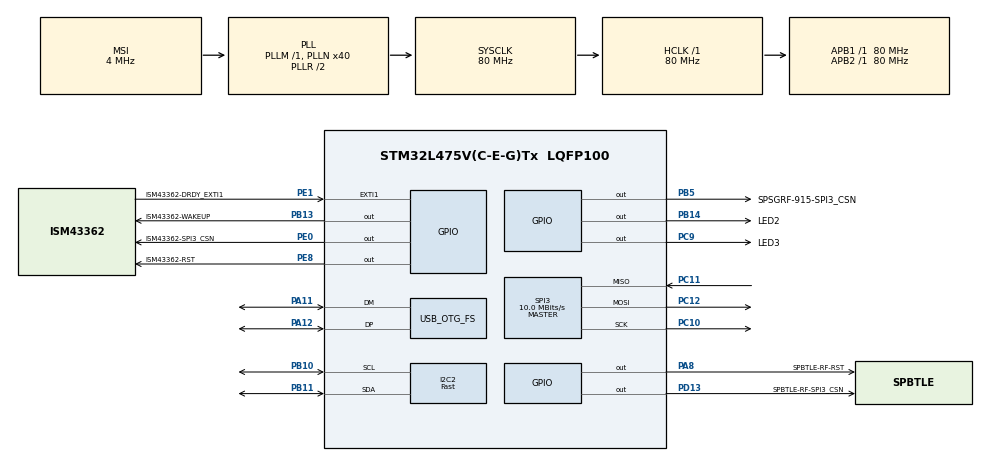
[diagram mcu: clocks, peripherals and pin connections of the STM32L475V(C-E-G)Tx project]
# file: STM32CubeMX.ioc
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Dma.I2C2_RX.0.Direction=DMA_PERIPH_TO_MEMORY
Dma.I2C2_RX.0.Instance=DMA1_Channel5
Dma.I2C2_RX.0.MemDataAlignment=DMA_MDATAALIGN_BYTE
Dma.I2C2_RX.0.MemInc=DMA_MINC_ENABLE
Dma.I2C2_RX.0.Mode=DMA_NORMAL
Dma.I2C2_RX.0.PeriphDataAlignment=DMA_PDATAALIGN_BYTE
Dma.I2C2_RX.0.PeriphInc=DMA_PINC_DISABLE
Dma.I2C2_RX.0.Priority=DMA_PRIORITY_LOW
Dma.I2C2_TX.1.Direction=DMA_MEMORY_TO_PERIPH
Dma.I2C2_TX.1.Instance=DMA1_Channel4
Dma.I2C2_TX.1.MemDataAlignment=DMA_MDATAALIGN_BYTE
Dma.I2C2_TX.1.MemInc=DMA_MINC_ENABLE
Dma.I2C2_TX.1.Mode=DMA_NORMAL
Dma.I2C2_TX.1.PeriphDataAlignment=DMA_PDATAALIGN_BYTE
Dma.I2C2_TX.1.PeriphInc=DMA_PINC_DISABLE
Dma.I2C2_TX.1.Priority=DMA_PRIORITY_LOW
Dma.Request0=I2C2_RX
Dma.Request1=I2C2_TX
I2C2.I2C_Speed_Mode=I2C_Fast
I2C2.Timing=0x00702991
Mcu.Family=STM32L4
Mcu.Name=STM32L475V(C-E-G)Tx
Mcu.Package=LQFP100
NVIC.DMA1_Channel4_IRQn=true\:14\:0\:true\:false\:true\:false\:true
NVIC.DMA1_Channel5_IRQn=true\:14\:0\:true\:false\:true\:false\:true
NVIC.EXTI1_IRQn=true\:13\:0\:true\:false\:true\:true\:true
NVIC.I2C2_ER_IRQn=true\:14\:0\:true\:false\:true\:true\:true
NVIC.I2C2_EV_IRQn=true\:14\:0\:true\:false\:true\:true\:true
NVIC.OTG_FS_IRQn=true\:14\:0\:true\:false\:true\:false\:true
NVIC.PriorityGroup=NVIC_PRIORITYGROUP_4
NVIC.SPI3_IRQn=true\:13\:0\:true\:false\:true\:true\:true
NVIC.TIM2_IRQn=true\:0\:0\:false\:false\:true\:false\:true
NVIC.TimeBase=TIM2_IRQn
NVIC.TimeBaseIP=TIM2
PA11.Mode=Device_Only
PA11.Signal=USB_OTG_FS_DM
PA12.Mode=Device_Only
PA12.Signal=USB_OTG_FS_DP
PA8.GPIO_Label=SPBTLE-RF-RST
PA8.PinState=GPIO_PIN_SET
PA8.Signal=GPIO_Output
PB10.GPIO_PuPdOD=GPIO_NOPULL
PB10.GPIO_Speed=GPIO_SPEED_FREQ_LOW
PB10.Mode=I2C
PB10.Signal=I2C2_SCL
PB11.GPIO_PuPdOD=GPIO_NOPULL
PB11.GPIO_Speed=GPIO_SPEED_FREQ_LOW
PB11.Mode=I2C
PB11.Signal=I2C2_SDA
PB13.GPIO_Label=ISM43362-WAKEUP
PB13.PinState=GPIO_PIN_SET
PB13.Signal=GPIO_Output
PB14.GPIO_Label=LED2
PB14.Signal=GPIO_Output
PB5.GPIO_Label=SPSGRF-915-SPI3_CSN
PB5.PinState=GPIO_PIN_SET
PB5.Signal=GPIO_Output
PC10.GPIO_Speed=GPIO_SPEED_FREQ_MEDIUM
PC10.Mode=Full_Duplex_Master
PC10.Signal=SPI3_SCK
PC11.GPIO_PuPd=GPIO_PULLUP
PC11.GPIO_Speed=GPIO_SPEED_FREQ_MEDIUM
PC11.Mode=Full_Duplex_Master
PC11.Signal=SPI3_MISO
PC12.GPIO_Speed=GPIO_SPEED_FREQ_MEDIUM
PC12.Mode=Full_Duplex_Master
PC12.Signal=SPI3_MOSI
PC9.GPIO_Label=LED3
PC9.GPIO_ModeDefaultOutputPP=GPIO_MODE_OUTPUT_PP
PC9.GPIO_PuPd=GPIO_NOPULL
PC9.Signal=GPIO_Output
PD13.GPIO_Label=SPBTLE-RF-SPI3_CSN
PD13.PinState=GPIO_PIN_SET
PD13.Signal=GPIO_Output
PE0.GPIO_Label=ISM43362-SPI3_CSN
PE0.GPIO_Speed=GPIO_SPEED_FREQ_MEDIUM
PE0.PinState=GPIO_PIN_SET
PE0.Signal=GPIO_Output
PE1.GPIO_Label=ISM43362-DRDY_EXTI1
PE1.Signal=GPXTI1
PE8.GPIO_Label=ISM43362-RST
PE8.PinState=GPIO_PIN_SET
PE8.Signal=GPIO_Output
ProjectManager.HeapSize=0x0
ProjectManager.StackSize=0x400
ProjectManager.TargetToolchain=STM32CubeIDE
RCC.ADCFreq_Value=48000000
RCC.AHBFreq_Value=80000000
RCC.APB1Freq_Value=80000000
RCC.APB1TimFreq_Value=80000000
RCC.APB2Freq_Value=80000000
RCC.APB2TimFreq_Value=80000000
RCC.CortexFreq_Value=80000000
RCC.HCLKFreq_Value=80000000
RCC.HSE_VALUE=8000000
RCC.HSI_VALUE=16000000
RCC.LSE_VALUE=32768
RCC.MSI_VALUE=4000000
RCC.PLLN=40
RCC.PLLSAI1N=24
RCC.SYSCLKFreq_VALUE=80000000
RCC.SYSCLKSource=RCC_SYSCLKSOURCE_PLLCLK
RCC.USBFreq_Value=48000000
RCC.VCOOutputFreq_Value=160000000
SPI3.BaudRatePrescaler=SPI_BAUDRATEPRESCALER_8
SPI3.CalculateBaudRate=10.0 MBits/s
SPI3.DataSize=SPI_DATASIZE_16BIT
SPI3.Direction=SPI_DIRECTION_2LINES
SPI3.Mode=SPI_MODE_MASTER
SPI3.VirtualType=VM_MASTER
USB_DEVICE.APP_TX_DATA_SIZE=2048
USB_DEVICE.CLASS_NAME_FS=CDC
USB_DEVICE.VirtualMode=Cdc
USB_DEVICE.VirtualModeFS=Cdc_FS
USB_OTG_FS.VirtualMode=Device_Only
VP_RNG_VS_RNG.Mode=RNG_Activate
VP_SYS_VS_tim2.Mode=TIM2
VP_USB_DEVICE_VS_USB_DEVICE_CDC_FS.Mode=CDC_FS
board=custom

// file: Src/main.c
/* USER CODE BEGIN Header */
/**
  ******************************************************************************
  * @file           : main.c
  * @brief          : Main program body
  ******************************************************************************
  ** This notice applies to any and all portions of this file
  * that are not between comment pairs USER CODE BEGIN and
  * USER CODE END. Other portions of this file, whether
  * inserted by the user or by software development tools
  * are owned by their respective copyright owners.
  *
  * COPYRIGHT(c) 2019 STMicroelectronics
  *
  * Redistribution and use in source and binary forms, with or without modification,
  * are permitted provided that the following conditions are met:
  *   1. Redistributions of source code must retain the above copyright notice,
  *      this list of conditions and the following disclaimer.
  *   2. Redistributions in binary form must reproduce the above copyright notice,
  *      this list of conditions and the following disclaimer in the documentation
  *      and/or other materials provided with the distribution.
  *   3. Neither the name of STMicroelectronics nor the names of its contributors
  *      may be used to endorse or promote products derived from this software
  *      without specific prior written permission.
  *
  * THIS SOFTWARE IS PROVIDED BY THE COPYRIGHT HOLDERS AND CONTRIBUTORS "AS IS"
  * AND ANY EXPRESS OR IMPLIED WARRANTIES, INCLUDING, BUT NOT LIMITED TO, THE
  * IMPLIED WARRANTIES OF MERCHANTABILITY AND FITNESS FOR A PARTICULAR PURPOSE ARE
  * DISCLAIMED. IN NO EVENT SHALL THE COPYRIGHT HOLDER OR CONTRIBUTORS BE LIABLE
  * FOR ANY DIRECT, INDIRECT, INCIDENTAL, SPECIAL, EXEMPLARY, OR CONSEQUENTIAL
  * DAMAGES (INCLUDING, BUT NOT LIMITED TO, PROCUREMENT OF SUBSTITUTE GOODS OR
  * SERVICES; LOSS OF USE, DATA, OR PROFITS; OR BUSINESS INTERRUPTION) HOWEVER
  * CAUSED AND ON ANY THEORY OF LIABILITY, WHETHER IN CONTRACT, STRICT LIABILITY,
  * OR TORT (INCLUDING NEGLIGENCE OR OTHERWISE) ARISING IN ANY WAY OUT OF THE USE
  * OF THIS SOFTWARE, EVEN IF ADVISED OF THE POSSIBILITY OF SUCH DAMAGE.
  *
  ******************************************************************************
  */
/* USER CODE END Header */

#include "main.h"
#include "usb_device.h"

/* USER CODE BEGIN Includes */
#include "es_wifi_io.h"
#include "usbd_cdc_if.h"
#include "StartApplication.hpp"

/* USER CODE END Includes */

I2C_HandleTypeDef hi2c2;
DMA_HandleTypeDef hdma_i2c2_rx;
DMA_HandleTypeDef hdma_i2c2_tx;

RNG_HandleTypeDef hrng;

SPI_HandleTypeDef hspi3;

void SystemClock_Config(void);
static void MX_GPIO_Init(void);
static void MX_DMA_Init(void);
static void MX_SPI3_Init(void);
static void MX_RNG_Init(void);
static void MX_I2C2_Init(void);

int main(void)
{
  /* USER CODE BEGIN 1 */

	/* Note: When the RTOS scheduler is started, the main stack pointer (MSP) is reset,
	* effectively wiping out all stack/local main() variables and objects. Do not declare
	* any C/C++ objects here. If objects need to be declared here, then change the code
	* within prvPortStartFirstTask() to retain the MSP value.
	*/

  /* USER CODE END 1 */

  /* MCU Configuration--------------------------------------------------------*/

  /* Reset of all peripherals, Initializes the Flash interface and the Systick. */
  HAL_Init();

  /* Configure the system clock */
  SystemClock_Config();

  /* Initialize all configured peripherals */
  MX_GPIO_Init();
  MX_DMA_Init();
  MX_USB_DEVICE_Init();
  MX_SPI3_Init();
  MX_RNG_Init();
  MX_I2C2_Init();
  /* USER CODE BEGIN 2 */
  StartApplication();

  /* USER CODE END 2 */

  /* Infinite loop */
  while (1)
  {

  }
}

void SystemClock_Config(void)
{
  RCC_OscInitTypeDef RCC_OscInitStruct = {0};
  RCC_ClkInitTypeDef RCC_ClkInitStruct = {0};
  RCC_PeriphCLKInitTypeDef PeriphClkInit = {0};

  /** Initializes the CPU, AHB and APB busses clocks
  */
  RCC_OscInitStruct.OscillatorType = RCC_OSCILLATORTYPE_MSI;
  RCC_OscInitStruct.MSIState = RCC_MSI_ON;
  RCC_OscInitStruct.MSICalibrationValue = 0;
  RCC_OscInitStruct.MSIClockRange = RCC_MSIRANGE_6;
  RCC_OscInitStruct.PLL.PLLState = RCC_PLL_ON;
  RCC_OscInitStruct.PLL.PLLSource = RCC_PLLSOURCE_MSI;
  RCC_OscInitStruct.PLL.PLLM = 1;
  RCC_OscInitStruct.PLL.PLLN = 40;
  RCC_OscInitStruct.PLL.PLLP = RCC_PLLP_DIV7;
  RCC_OscInitStruct.PLL.PLLQ = RCC_PLLQ_DIV2;
  RCC_OscInitStruct.PLL.PLLR = RCC_PLLR_DIV2;
  if (HAL_RCC_OscConfig(&RCC_OscInitStruct) != HAL_OK)
  {
    Error_Handler();
  }
  /** Initializes the CPU, AHB and APB busses clocks
  */
  RCC_ClkInitStruct.ClockType = RCC_CLOCKTYPE_HCLK|RCC_CLOCKTYPE_SYSCLK
                              |RCC_CLOCKTYPE_PCLK1|RCC_CLOCKTYPE_PCLK2;
  RCC_ClkInitStruct.SYSCLKSource = RCC_SYSCLKSOURCE_PLLCLK;
  RCC_ClkInitStruct.AHBCLKDivider = RCC_SYSCLK_DIV1;
  RCC_ClkInitStruct.APB1CLKDivider = RCC_HCLK_DIV1;
  RCC_ClkInitStruct.APB2CLKDivider = RCC_HCLK_DIV1;

  if (HAL_RCC_ClockConfig(&RCC_ClkInitStruct, FLASH_LATENCY_4) != HAL_OK)
  {
    Error_Handler();
  }
  PeriphClkInit.PeriphClockSelection = RCC_PERIPHCLK_I2C2|RCC_PERIPHCLK_USB
                              |RCC_PERIPHCLK_RNG;
  PeriphClkInit.I2c2ClockSelection = RCC_I2C2CLKSOURCE_PCLK1;
  PeriphClkInit.UsbClockSelection = RCC_USBCLKSOURCE_PLLSAI1;
  PeriphClkInit.RngClockSelection = RCC_RNGCLKSOURCE_PLLSAI1;
  PeriphClkInit.PLLSAI1.PLLSAI1Source = RCC_PLLSOURCE_MSI;
  PeriphClkInit.PLLSAI1.PLLSAI1M = 1;
  PeriphClkInit.PLLSAI1.PLLSAI1N = 24;
  PeriphClkInit.PLLSAI1.PLLSAI1P = RCC_PLLP_DIV7;
  PeriphClkInit.PLLSAI1.PLLSAI1Q = RCC_PLLQ_DIV2;
  PeriphClkInit.PLLSAI1.PLLSAI1R = RCC_PLLR_DIV2;
  PeriphClkInit.PLLSAI1.PLLSAI1ClockOut = RCC_PLLSAI1_48M2CLK;
  if (HAL_RCCEx_PeriphCLKConfig(&PeriphClkInit) != HAL_OK)
  {
    Error_Handler();
  }
  /** Configure the main internal regulator output voltage
  */
  if (HAL_PWREx_ControlVoltageScaling(PWR_REGULATOR_VOLTAGE_SCALE1) != HAL_OK)
  {
    Error_Handler();
  }
}

static void MX_I2C2_Init(void)
{

  hi2c2.Instance = I2C2;
  hi2c2.Init.Timing = 0x00702991;
  hi2c2.Init.OwnAddress1 = 0;
  hi2c2.Init.AddressingMode = I2C_ADDRESSINGMODE_7BIT;
  hi2c2.Init.DualAddressMode = I2C_DUALADDRESS_DISABLE;
  hi2c2.Init.OwnAddress2 = 0;
  hi2c2.Init.OwnAddress2Masks = I2C_OA2_NOMASK;
  hi2c2.Init.GeneralCallMode = I2C_GENERALCALL_DISABLE;
  hi2c2.Init.NoStretchMode = I2C_NOSTRETCH_DISABLE;
  if (HAL_I2C_Init(&hi2c2) != HAL_OK)
  {
    Error_Handler();
  }
  /** Configure Analogue filter
  */
  if (HAL_I2CEx_ConfigAnalogFilter(&hi2c2, I2C_ANALOGFILTER_ENABLE) != HAL_OK)
  {
    Error_Handler();
  }
  /** Configure Digital filter
  */
  if (HAL_I2CEx_ConfigDigitalFilter(&hi2c2, 0) != HAL_OK)
  {
    Error_Handler();
  }

}

static void MX_RNG_Init(void)
{

  hrng.Instance = RNG;
  if (HAL_RNG_Init(&hrng) != HAL_OK)
  {
    Error_Handler();
  }

}

static void MX_SPI3_Init(void)
{

  /* SPI3 parameter configuration*/
  hspi3.Instance = SPI3;
  hspi3.Init.Mode = SPI_MODE_MASTER;
  hspi3.Init.Direction = SPI_DIRECTION_2LINES;
  hspi3.Init.DataSize = SPI_DATASIZE_16BIT;
  hspi3.Init.CLKPolarity = SPI_POLARITY_LOW;
  hspi3.Init.CLKPhase = SPI_PHASE_1EDGE;
  hspi3.Init.NSS = SPI_NSS_SOFT;
  hspi3.Init.BaudRatePrescaler = SPI_BAUDRATEPRESCALER_8;
  hspi3.Init.FirstBit = SPI_FIRSTBIT_MSB;
  hspi3.Init.TIMode = SPI_TIMODE_DISABLE;
  hspi3.Init.CRCCalculation = SPI_CRCCALCULATION_DISABLE;
  hspi3.Init.CRCPolynomial = 7;
  hspi3.Init.CRCLength = SPI_CRC_LENGTH_DATASIZE;
  hspi3.Init.NSSPMode = SPI_NSS_PULSE_ENABLE;
  if (HAL_SPI_Init(&hspi3) != HAL_OK)
  {
    Error_Handler();
  }

}

static void MX_DMA_Init(void)
{

  /* DMA controller clock enable */
  __HAL_RCC_DMA1_CLK_ENABLE();

  /* DMA interrupt init */
  /* DMA1_Channel4_IRQn interrupt configuration */
  HAL_NVIC_SetPriority(DMA1_Channel4_IRQn, 14, 0);
  HAL_NVIC_EnableIRQ(DMA1_Channel4_IRQn);
  /* DMA1_Channel5_IRQn interrupt configuration */
  HAL_NVIC_SetPriority(DMA1_Channel5_IRQn, 14, 0);
  HAL_NVIC_EnableIRQ(DMA1_Channel5_IRQn);

}

static void MX_GPIO_Init(void)
{
  GPIO_InitTypeDef GPIO_InitStruct = {0};

  /* GPIO Ports Clock Enable */
  __HAL_RCC_GPIOE_CLK_ENABLE();
  __HAL_RCC_GPIOB_CLK_ENABLE();
  __HAL_RCC_GPIOD_CLK_ENABLE();
  __HAL_RCC_GPIOC_CLK_ENABLE();
  __HAL_RCC_GPIOA_CLK_ENABLE();

  /*Configure GPIO pin Output Level */
  HAL_GPIO_WritePin(GPIOE, ISM43362_RST_Pin|ISM43362_SPI3_CSN_Pin, GPIO_PIN_SET);

  /*Configure GPIO pin Output Level */
  HAL_GPIO_WritePin(GPIOB, ISM43362_WAKEUP_Pin|SPSGRF_915_SPI3_CSN_Pin, GPIO_PIN_SET);

  /*Configure GPIO pin Output Level */
  HAL_GPIO_WritePin(LED2_GPIO_Port, LED2_Pin, GPIO_PIN_RESET);

  /*Configure GPIO pin Output Level */
  HAL_GPIO_WritePin(SPBTLE_RF_SPI3_CSN_GPIO_Port, SPBTLE_RF_SPI3_CSN_Pin, GPIO_PIN_SET);

  /*Configure GPIO pin Output Level */
  HAL_GPIO_WritePin(LED3_GPIO_Port, LED3_Pin, GPIO_PIN_RESET);

  /*Configure GPIO pin Output Level */
  HAL_GPIO_WritePin(SPBTLE_RF_RST_GPIO_Port, SPBTLE_RF_RST_Pin, GPIO_PIN_SET);

  /*Configure GPIO pin : ISM43362_RST_Pin */
  GPIO_InitStruct.Pin = ISM43362_RST_Pin;
  GPIO_InitStruct.Mode = GPIO_MODE_OUTPUT_PP;
  GPIO_InitStruct.Pull = GPIO_NOPULL;
  GPIO_InitStruct.Speed = GPIO_SPEED_FREQ_LOW;
  HAL_GPIO_Init(ISM43362_RST_GPIO_Port, &GPIO_InitStruct);

  /*Configure GPIO pins : ISM43362_WAKEUP_Pin LED2_Pin SPSGRF_915_SPI3_CSN_Pin */
  GPIO_InitStruct.Pin = ISM43362_WAKEUP_Pin|LED2_Pin|SPSGRF_915_SPI3_CSN_Pin;
  GPIO_InitStruct.Mode = GPIO_MODE_OUTPUT_PP;
  GPIO_InitStruct.Pull = GPIO_NOPULL;
  GPIO_InitStruct.Speed = GPIO_SPEED_FREQ_LOW;
  HAL_GPIO_Init(GPIOB, &GPIO_InitStruct);

  /*Configure GPIO pin : SPBTLE_RF_SPI3_CSN_Pin */
  GPIO_InitStruct.Pin = SPBTLE_RF_SPI3_CSN_Pin;
  GPIO_InitStruct.Mode = GPIO_MODE_OUTPUT_PP;
  GPIO_InitStruct.Pull = GPIO_NOPULL;
  GPIO_InitStruct.Speed = GPIO_SPEED_FREQ_LOW;
  HAL_GPIO_Init(SPBTLE_RF_SPI3_CSN_GPIO_Port, &GPIO_InitStruct);

  /*Configure GPIO pin : LED3_Pin */
  GPIO_InitStruct.Pin = LED3_Pin;
  GPIO_InitStruct.Mode = GPIO_MODE_OUTPUT_PP;
  GPIO_InitStruct.Pull = GPIO_NOPULL;
  GPIO_InitStruct.Speed = GPIO_SPEED_FREQ_LOW;
  HAL_GPIO_Init(LED3_GPIO_Port, &GPIO_InitStruct);

  /*Configure GPIO pin : SPBTLE_RF_RST_Pin */
  GPIO_InitStruct.Pin = SPBTLE_RF_RST_Pin;
  GPIO_InitStruct.Mode = GPIO_MODE_OUTPUT_PP;
  GPIO_InitStruct.Pull = GPIO_NOPULL;
  GPIO_InitStruct.Speed = GPIO_SPEED_FREQ_LOW;
  HAL_GPIO_Init(SPBTLE_RF_RST_GPIO_Port, &GPIO_InitStruct);

  /*Configure GPIO pin : ISM43362_SPI3_CSN_Pin */
  GPIO_InitStruct.Pin = ISM43362_SPI3_CSN_Pin;
  GPIO_InitStruct.Mode = GPIO_MODE_OUTPUT_PP;
  GPIO_InitStruct.Pull = GPIO_NOPULL;
  GPIO_InitStruct.Speed = GPIO_SPEED_FREQ_MEDIUM;
  HAL_GPIO_Init(ISM43362_SPI3_CSN_GPIO_Port, &GPIO_InitStruct);

  /*Configure GPIO pin : ISM43362_DRDY_EXTI1_Pin */
  GPIO_InitStruct.Pin = ISM43362_DRDY_EXTI1_Pin;
  GPIO_InitStruct.Mode = GPIO_MODE_IT_RISING;
  GPIO_InitStruct.Pull = GPIO_NOPULL;
  HAL_GPIO_Init(ISM43362_DRDY_EXTI1_GPIO_Port, &GPIO_InitStruct);

  /* EXTI interrupt init*/
  HAL_NVIC_SetPriority(EXTI1_IRQn, 13, 0);
  HAL_NVIC_EnableIRQ(EXTI1_IRQn);

}

/* USER CODE BEGIN 4 */
/**
  * @brief  EXTI line detection callback.
  * @param  GPIO_Pin: Specifies the port pin connected to corresponding EXTI line.
  * @retval None
  */
void HAL_GPIO_EXTI_Callback(uint16_t GPIO_Pin)
{
  switch (GPIO_Pin)
  {
	case (ISM43362_DRDY_EXTI1_Pin):
	{
		SPI_WIFI_ISR();
		break;
	}

    default:
    {
      break;
    }
  }
}
/* USER CODE END 4 */

void HAL_TIM_PeriodElapsedCallback(TIM_HandleTypeDef *htim)
{
  if (htim->Instance == TIM2) {
    HAL_IncTick();
  }
}

void Error_Handler(void)
{
  /* USER CODE BEGIN Error_Handler_Debug */
  /* User can add his own implementation to report the HAL error return state */
#define LED3_Register ()
	for (;;) {
		HAL_GPIO_TogglePin(LED3_GPIO_Port, LED3_Pin);
	    HAL_Delay(200);
	}

  /* USER CODE END Error_Handler_Debug */
}

/************************ (C) COPYRIGHT STMicroelectronics *****END OF FILE****/
